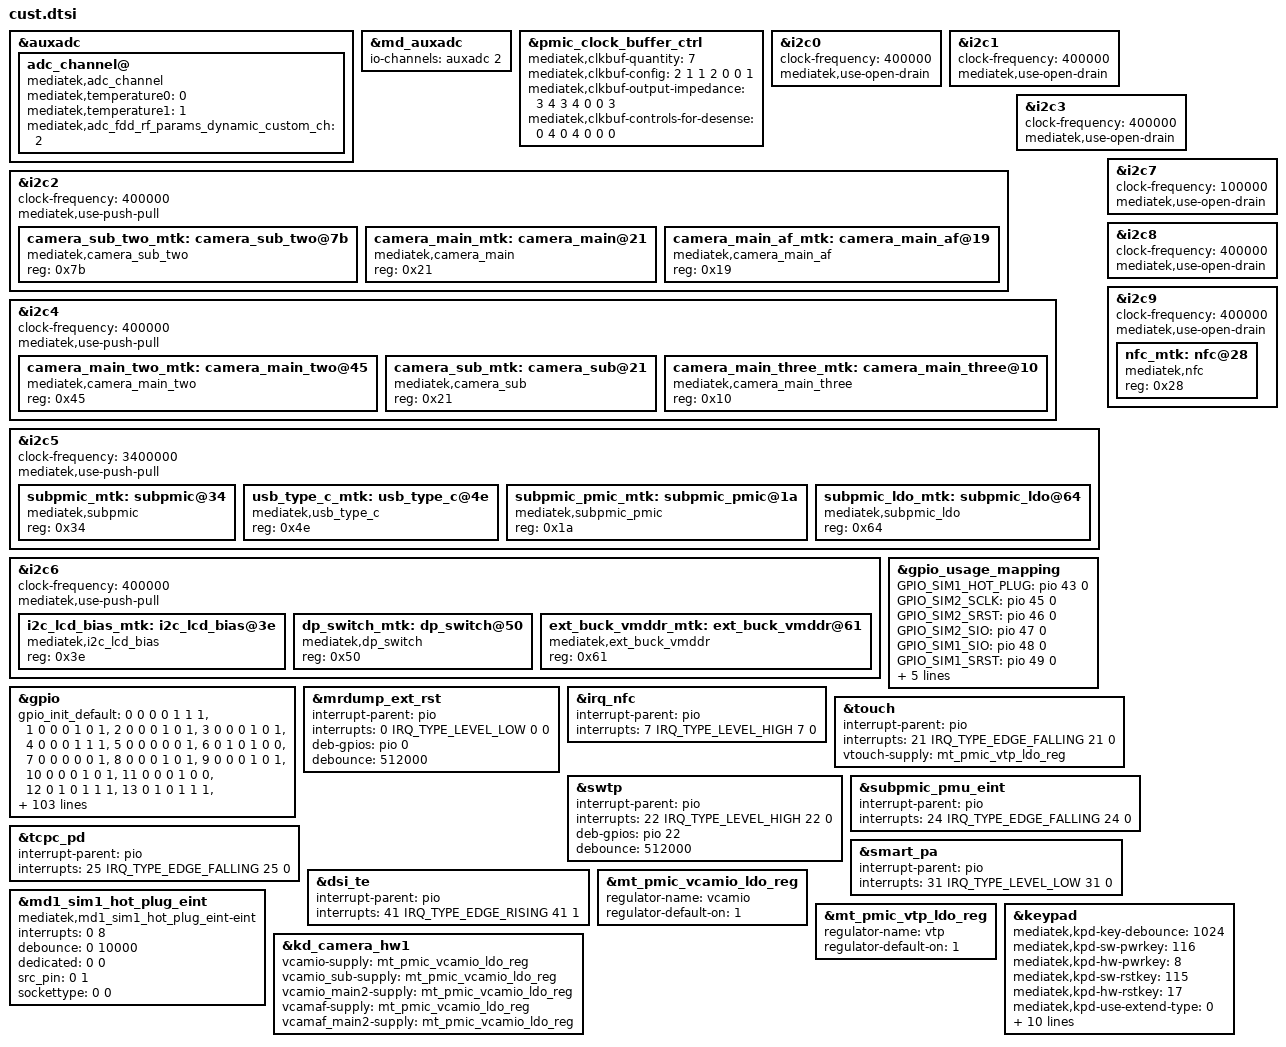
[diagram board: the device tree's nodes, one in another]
/*
 * Generated by MTK SP DrvGen Version: 3.5.160809 for MT6893.
 * 2021-10-15 06:06:19
 * Do Not Modify The File.
 * Copyright Mediatek Inc. (c) 2016.
*/

/*************************
 * ADC DTSI File
*************************/

&auxadc {
	adc_channel@ {
		compatible = "mediatek,adc_channel";
		mediatek,temperature0 = <0>;
		mediatek,temperature1 = <1>;
		mediatek,adc_fdd_rf_params_dynamic_custom_ch = <2>;
		status = "okay";
	};
};
&md_auxadc {
	io-channels = <&auxadc 2>;
};


/*************************
 * CLK_BUF DTSI File
*************************/

&pmic_clock_buffer_ctrl {
	mediatek,clkbuf-quantity = <7>;
	mediatek,clkbuf-config = <2 1 1 2 0 0 1>;
	mediatek,clkbuf-output-impedance = <3 4 3 4 0 0 3>;
	mediatek,clkbuf-controls-for-desense = <0 4 0 4 0 0 0>;
	status = "okay";
};


/*************************
 * I2C DTSI File
*************************/

&i2c0 {
	#address-cells = <1>;
	#size-cells = <0>;
	clock-frequency = <400000>;
	mediatek,use-open-drain;
};

&i2c1 {
	#address-cells = <1>;
	#size-cells = <0>;
	clock-frequency = <400000>;
	mediatek,use-open-drain;
};

&i2c2 {
	#address-cells = <1>;
	#size-cells = <0>;
	clock-frequency = <400000>;
	mediatek,use-push-pull;
	camera_sub_two_mtk:camera_sub_two@7b {
		compatible = "mediatek,camera_sub_two";
		reg = <0x7b>;
		status = "okay";
	};

	camera_main_mtk:camera_main@21 {
		compatible = "mediatek,camera_main";
		reg = <0x21>;
		status = "okay";
	};

	camera_main_af_mtk:camera_main_af@19 {
		compatible = "mediatek,camera_main_af";
		reg = <0x19>;
		status = "okay";
	};

};

&i2c3 {
	#address-cells = <1>;
	#size-cells = <0>;
	clock-frequency = <400000>;
	mediatek,use-open-drain;
};

&i2c4 {
	#address-cells = <1>;
	#size-cells = <0>;
	clock-frequency = <400000>;
	mediatek,use-push-pull;
	camera_main_two_mtk:camera_main_two@45 {
		compatible = "mediatek,camera_main_two";
		reg = <0x45>;
		status = "okay";
	};

	camera_sub_mtk:camera_sub@21 {
		compatible = "mediatek,camera_sub";
		reg = <0x21>;
		status = "okay";
	};

	camera_main_three_mtk:camera_main_three@10 {
		compatible = "mediatek,camera_main_three";
		reg = <0x10>;
		status = "okay";
	};

};

&i2c5 {
	#address-cells = <1>;
	#size-cells = <0>;
	clock-frequency = <3400000>;
	mediatek,use-push-pull;
	subpmic_mtk:subpmic@34 {
		compatible = "mediatek,subpmic";
		reg = <0x34>;
		status = "okay";
	};

	usb_type_c_mtk:usb_type_c@4e {
		compatible = "mediatek,usb_type_c";
		reg = <0x4e>;
		status = "okay";
	};

	subpmic_pmic_mtk:subpmic_pmic@1a {
		compatible = "mediatek,subpmic_pmic";
		reg = <0x1a>;
		status = "okay";
	};

	subpmic_ldo_mtk:subpmic_ldo@64 {
		compatible = "mediatek,subpmic_ldo";
		reg = <0x64>;
		status = "okay";
	};

};

&i2c6 {
	#address-cells = <1>;
	#size-cells = <0>;
	clock-frequency = <400000>;
	mediatek,use-push-pull;
	i2c_lcd_bias_mtk:i2c_lcd_bias@3e {
		compatible = "mediatek,i2c_lcd_bias";
		reg = <0x3e>;
		status = "okay";
	};

	dp_switch_mtk:dp_switch@50 {
		compatible = "mediatek,dp_switch";
		reg = <0x50>;
		status = "okay";
	};

	ext_buck_vmddr_mtk:ext_buck_vmddr@61 {
		compatible = "mediatek,ext_buck_vmddr";
		reg = <0x61>;
		status = "okay";
	};

};

&i2c7 {
	#address-cells = <1>;
	#size-cells = <0>;
	clock-frequency = <100000>;
	mediatek,use-open-drain;
};

&i2c8 {
	#address-cells = <1>;
	#size-cells = <0>;
	clock-frequency = <400000>;
	mediatek,use-open-drain;
};

&i2c9 {
	#address-cells = <1>;
	#size-cells = <0>;
	clock-frequency = <400000>;
	mediatek,use-open-drain;
	nfc_mtk:nfc@28 {
		compatible = "mediatek,nfc";
		reg = <0x28>;
		status = "okay";
	};

};



/*************************
 * GPIO DTSI File
*************************/

&gpio_usage_mapping {
	GPIO_SIM1_HOT_PLUG = <&pio 43 0>;
	GPIO_SIM2_SCLK = <&pio 45 0>;
	GPIO_SIM2_SRST = <&pio 46 0>;
	GPIO_SIM2_SIO = <&pio 47 0>;
	GPIO_SIM1_SIO = <&pio 48 0>;
	GPIO_SIM1_SRST = <&pio 49 0>;
	GPIO_SIM1_SCLK = <&pio 50 0>;
	GPIO_FDD_BAND_SUPPORT_DETECT_1ST_PIN = <&pio 63 0>;
	GPIO_FDD_BAND_SUPPORT_DETECT_2ND_PIN = <&pio 64 0>;
	GPIO_FDD_BAND_SUPPORT_DETECT_3RD_PIN = <&pio 65 0>;
	GPIO_FDD_BAND_SUPPORT_DETECT_4TH_PIN = <&pio 66 0>;
};

&gpio{
	gpio_init_default = <0 0 0 0 1 1 1>,
		<1 0 0 0 1 0 1>,
		<2 0 0 0 1 0 1>,
		<3 0 0 0 1 0 1>,
		<4 0 0 0 1 1 1>,
		<5 0 0 0 0 0 1>,
		<6 0 1 0 1 0 0>,
		<7 0 0 0 0 0 1>,
		<8 0 0 0 1 0 1>,
		<9 0 0 0 1 0 1>,
		<10 0 0 0 1 0 1>,
		<11 0 0 0 1 0 0>,
		<12 0 1 0 1 1 1>,
		<13 0 1 0 1 1 1>,
		<14 0 1 0 0 0 0>,
		<15 0 0 0 0 0 0>,
		<16 0 1 0 1 0 0>,
		<17 1 0 0 1 0 0>,
		<18 2 0 0 1 0 1>,
		<19 0 1 0 1 0 1>,
		<20 0 1 0 1 0 1>,
		<21 0 0 0 1 1 1>,
		<22 0 0 0 1 1 1>,
		<23 0 0 0 1 1 1>,
		<24 0 0 0 1 1 1>,
		<25 0 0 0 1 1 1>,
		<26 0 1 0 1 0 1>,
		<27 0 1 1 1 0 1>,
		<28 0 1 0 1 0 1>,
		<29 0 1 0 1 0 1>,
		<30 0 1 0 1 0 1>,
		<31 0 0 0 1 1 1>,
		<32 1 0 0 0 0 1>,
		<33 1 0 0 0 0 1>,
		<34 1 0 0 1 0 1>,
		<35 1 0 0 0 0 1>,
		<36 1 1 0 0 0 0>,
		<37 1 1 0 0 0 0>,
		<38 1 0 0 1 1 0>,
		<39 1 1 0 1 0 0>,
		<40 1 0 0 0 0 0>,
		<41 1 0 0 1 0 0>,
		<42 0 1 0 1 0 0>,
		<43 1 0 0 1 1 1>,
		<44 0 0 0 1 0 0>,
		<45 1 0 0 0 0 1>,
		<46 1 0 0 0 0 1>,
		<47 1 0 0 1 1 1>,
		<48 1 0 0 1 1 1>,
		<49 1 0 0 0 0 1>,
		<50 1 0 0 0 0 1>,
		<51 0 1 0 1 0 1>,
		<52 1 0 0 1 1 1>,
		<53 1 0 0 1 1 1>,
		<54 0 1 0 1 0 1>,
		<55 1 0 0 1 0 1>,
		<56 1 0 0 1 0 1>,
		<57 1 0 0 1 0 0>,
		<58 1 0 0 1 0 0>,
		<59 1 0 0 1 0 1>,
		<60 1 0 0 1 0 1>,
		<61 1 0 0 1 0 0>,
		<62 1 0 0 1 0 1>,
		<63 0 0 0 1 0 0>,
		<64 0 0 0 1 0 0>,
		<65 0 0 0 1 0 0>,
		<66 0 0 0 1 0 0>,
		<67 1 0 0 1 0 0>,
		<68 1 0 0 1 0 0>,
		<69 1 0 0 1 0 0>,
		<70 1 0 0 1 0 0>,
		<71 1 0 0 1 0 0>,
		<72 1 0 0 1 0 0>,
		<73 1 0 0 1 0 0>,
		<74 1 0 0 1 0 0>,
		<75 1 0 0 1 0 0>,
		<76 1 0 0 1 0 0>,
		<77 1 0 0 1 0 0>,
		<78 1 0 0 1 0 0>,
		<79 1 0 0 1 0 0>,
		<80 1 0 0 1 0 0>,
		<81 1 0 0 1 0 0>,
		<82 1 0 0 1 0 0>,
		<83 1 0 0 1 0 0>,
		<84 1 0 0 1 0 0>,
		<85 1 0 0 1 0 0>,
		<86 1 0 0 1 0 0>,
		<87 1 0 0 1 0 0>,
		<88 1 0 0 1 0 0>,
		<89 1 0 0 0 0 1>,
		<90 1 0 0 0 0 1>,
		<92 1 0 0 1 1 0>,
		<93 1 0 0 1 1 0>,
		<94 0 0 0 0 0 0>,
		<95 0 1 0 1 0 0>,
		<96 7 0 0 1 0 0>,
		<97 7 0 0 1 0 0>,
		<98 7 0 0 1 0 0>,
		<99 7 0 0 0 0 0>,
		<100 7 0 0 1 0 0>,
		<101 7 0 0 1 0 0>,
		<102 7 0 0 1 0 0>,
		<103 2 0 0 0 0 0>,
		<104 2 0 0 1 0 0>,
		<105 2 0 0 1 0 0>,
		<106 2 0 0 1 0 0>,
		<107 7 0 0 1 0 1>,
		<108 7 0 0 1 0 0>,
		<109 7 0 0 1 0 0>,
		<110 0 1 0 1 0 0>,
		<111 0 1 0 1 0 0>,
		<112 0 1 0 1 0 0>,
		<113 0 1 0 1 0 0>,
		<114 2 0 0 1 0 0>,
		<115 2 0 0 0 0 0>,
		<116 2 0 0 0 0 0>,
		<117 2 0 0 0 0 0>,
		<118 2 0 0 1 1 1>,
		<119 2 0 0 1 1 1>,
		<120 1 0 0 1 1 1>,
		<121 1 0 0 1 1 1>,
		<122 1 0 0 1 1 1>,
		<123 1 0 0 1 1 1>,
		<124 1 0 0 1 1 1>,
		<125 1 0 0 1 1 1>,
		<126 5 0 0 1 1 1>,
		<127 5 0 0 1 1 1>,
		<128 0 1 0 1 0 1>,
		<129 0 1 0 1 0 0>,
		<130 0 1 0 1 0 0>,
		<131 0 1 0 1 0 0>,
		<132 1 0 0 1 0 0>,
		<133 0 1 0 1 0 0>,
		<134 0 1 0 1 0 0>,
		<135 0 0 0 0 0 1>,
		<136 1 0 0 0 0 0>,
		<137 0 0 0 1 0 0>,
		<138 0 1 0 1 0 0>,
		<139 1 0 0 1 1 1>,
		<140 1 0 0 1 1 1>,
		<141 1 0 0 1 1 1>,
		<142 1 0 0 1 1 1>,
		<143 0 1 0 1 0 0>,
		<144 0 1 0 1 0 0>,
		<145 0 1 0 1 0 0>,
		<146 0 1 0 1 0 0>,
		<147 0 0 0 0 0 1>,
		<148 0 1 0 1 0 0>,
		<149 1 0 0 0 0 0>,
		<150 1 0 0 0 0 0>,
		<151 1 0 0 0 0 0>,
		<152 0 0 0 1 0 0>,
		<153 1 0 0 0 0 0>,
		<154 1 0 0 1 1 0>,
		<155 0 0 0 0 0 0>,
		<156 1 1 0 0 0 0>,
		<157 0 1 0 0 0 0>,
		<158 1 0 0 1 0 0>,
		<159 1 1 0 0 0 0>,
		<160 1 0 0 1 1 1>,
		<161 1 0 0 1 1 1>,
		<162 0 1 0 1 0 1>,
		<163 0 1 0 1 0 1>,
		<164 0 0 0 1 0 1>,
		<165 1 0 0 1 0 1>,
		<166 1 0 0 1 0 1>,
		<167 0 0 0 1 0 1>,
		<168 6 0 0 1 1 1>,
		<169 6 0 0 1 1 1>,
		<170 6 0 0 1 1 1>,
		<171 6 0 0 1 1 1>,
		<172 0 0 0 1 0 0>,
		<173 0 0 0 1 0 0>,
		<174 0 0 0 1 0 0>,
		<175 0 0 0 1 0 0>,
		<176 0 0 0 1 0 0>,
		<177 0 0 0 1 0 0>,
		<178 0 0 0 1 0 0>,
		<179 0 0 0 1 0 0>,
		<180 0 0 0 1 0 0>,
		<181 0 0 0 1 0 0>,
		<182 0 0 0 1 0 0>,
		<187 0 1 0 1 0 0>,
		<189 0 1 0 1 0 1>,
		<191 0 1 0 1 0 1>,
		<192 0 1 0 1 0 1>,
		<193 0 0 0 0 0 1>,
		<195 1 0 0 0 0 0>,
		<196 1 0 0 0 0 1>,
		<197 1 0 0 0 0 1>,
		<198 1 0 0 0 0 1>,
		<199 1 0 0 1 0 1>,
		<200 3 0 0 1 1 1>,
		<201 3 0 0 1 1 1>,
		<202 1 0 0 1 1 1>,
		<203 1 0 0 1 1 1>,
		<204 1 0 0 1 1 1>,
		<205 1 0 0 1 1 1>,
		<206 1 0 0 0 0 0>,
		<207 1 0 0 0 0 0>,
		<208 1 0 0 0 0 0>,
		<209 1 0 0 1 0 0>,
		<210 1 0 0 0 0 0>,
		<211 1 0 0 0 0 0>,
		<212 1 0 0 0 0 0>,
		<213 1 0 0 1 0 0>,
		<214 1 0 0 0 0 1>,
		<215 1 0 0 0 0 1>,
		<216 1 0 0 0 0 1>,
		<217 1 0 0 0 0 1>,
		<218 1 0 0 1 0 1>,
		<219 1 0 0 1 0 1>,
		<220 0 0 0 1 0 0>,
		<221 0 0 0 1 0 0>,
		<222 0 0 0 1 0 0>,
		<223 0 0 0 1 0 0>,
		<224 0 0 0 1 0 0>,
		<225 0 0 0 1 0 0>,
		<226 0 0 0 1 0 0>;
};


/*************************
 * EINT DTSI File
*************************/

#include <dt-bindings/interrupt-controller/irq.h>
#include <dt-bindings/interrupt-controller/arm-gic.h>

&mrdump_ext_rst {
	interrupt-parent = <&pio>;
	interrupts = <0 IRQ_TYPE_LEVEL_LOW 0 0>;
	deb-gpios = <&pio 0 0>;
	debounce = <512000>;
	status = "okay";
};

&irq_nfc {
	interrupt-parent = <&pio>;
	interrupts = <7 IRQ_TYPE_LEVEL_HIGH 7 0>;
	status = "okay";
};

&touch {
	interrupt-parent = <&pio>;
	interrupts = <21 IRQ_TYPE_EDGE_FALLING 21 0>;
	status = "okay";
};

&swtp {
	interrupt-parent = <&pio>;
	interrupts = <22 IRQ_TYPE_LEVEL_HIGH 22 0>;
	deb-gpios = <&pio 22 0>;
	debounce = <512000>;
	status = "okay";
};

&subpmic_pmu_eint {
	interrupt-parent = <&pio>;
	interrupts = <24 IRQ_TYPE_EDGE_FALLING 24 0>;
	status = "okay";
};

&tcpc_pd {
	interrupt-parent = <&pio>;
	interrupts = <25 IRQ_TYPE_EDGE_FALLING 25 0>;
	status = "okay";
};

&smart_pa {
	interrupt-parent = <&pio>;
	interrupts = <31 IRQ_TYPE_LEVEL_LOW 31 0>;
	status = "okay";
};

&dsi_te {
	interrupt-parent = <&pio>;
	interrupts = <41 IRQ_TYPE_EDGE_RISING 41 1>;
	status = "okay";
};



/*************************
 * MD1_EINT DTSI File
*************************/

&md1_sim1_hot_plug_eint {
	compatible = "mediatek,md1_sim1_hot_plug_eint-eint";
	interrupts = <0 8>;
	debounce = <0 10000>;
	dedicated = <0 0>;
	src_pin = <0 1>;
	sockettype = <0 0>;
	status = "okay";
};



/*************************
 * PMIC DTSI File
*************************/

&mt_pmic_vcamio_ldo_reg {
	regulator-name = "vcamio";
	regulator-default-on = <1>; /* 0:skip, 1: off, 2:on */
	status = "okay";
};
&mt_pmic_vtp_ldo_reg {
	regulator-name = "vtp";
	regulator-default-on = <1>; /* 0:skip, 1: off, 2:on */
	status = "okay";
};

&kd_camera_hw1 {
	vcamio-supply = <&mt_pmic_vcamio_ldo_reg>;
	vcamio_sub-supply = <&mt_pmic_vcamio_ldo_reg>;
	vcamio_main2-supply = <&mt_pmic_vcamio_ldo_reg>;
	vcamaf-supply = <&mt_pmic_vcamio_ldo_reg>;
	vcamaf_main2-supply = <&mt_pmic_vcamio_ldo_reg>;
	status = "okay";
};

&touch {
	vtouch-supply = <&mt_pmic_vtp_ldo_reg>;
	status = "okay";
};


/*************************
 * POWER DTSI File
*************************/



/*************************
 * KPD DTSI File
*************************/

&keypad {
	mediatek,kpd-key-debounce = <1024>;
	mediatek,kpd-sw-pwrkey = <116>;
	mediatek,kpd-hw-pwrkey = <8>;
	mediatek,kpd-sw-rstkey  = <115>;
	mediatek,kpd-hw-rstkey = <17>;
	mediatek,kpd-use-extend-type = <0>;
	/*HW Keycode [0~71] -> Linux Keycode*/
	mediatek,kpd-hw-map-num = <72>;
	mediatek,kpd-hw-init-map = <114 0 0 0 0 0 0 0 0 0 0 0 0 0 0 0 0 0 0 0 0 0 0 0 0 0 0 0 0 0 0 0 0 0 0 0 0 0 0 0 0 0 0 0 0 0 0 0 0 0 0 0 0 0 0 0 0 0 0 0 0 0 0 0 0 0 0 0 0 0 0 0 >;
	mediatek,kpd-pwrkey-eint-gpio = <0>;
	mediatek,kpd-pwkey-gpio-din  = <0>;
	mediatek,kpd-hw-dl-key0 = <17>;
	mediatek,kpd-hw-dl-key1 = <0>;
	mediatek,kpd-hw-dl-key2 = <8>;
	mediatek,kpd-hw-recovery-key = <17>;
	mediatek,kpd-hw-factory-key = <0>;
	status = "okay";
};


